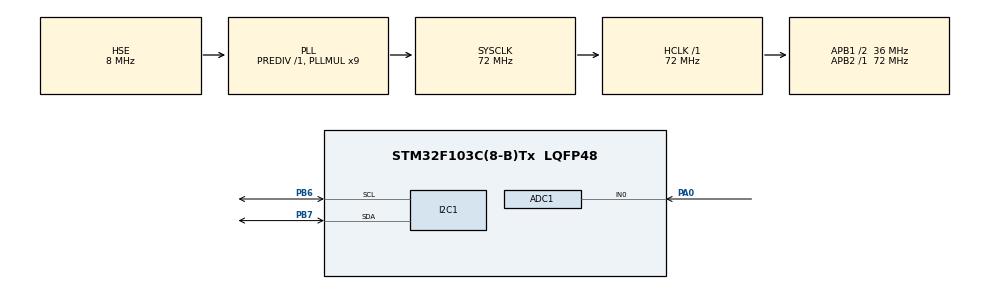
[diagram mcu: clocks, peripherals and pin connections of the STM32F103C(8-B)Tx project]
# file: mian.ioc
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ADC1.Channel-0\#ChannelRegularConversion=ADC_CHANNEL_0
ADC1.NbrOfConversionFlag=1
ADC1.Rank-0\#ChannelRegularConversion=1
ADC1.SamplingTime-0\#ChannelRegularConversion=ADC_SAMPLETIME_1CYCLE_5
ADC1.master=1
Mcu.Family=STM32F1
Mcu.Name=STM32F103C(8-B)Tx
Mcu.Package=LQFP48
NVIC.PriorityGroup=NVIC_PRIORITYGROUP_4
PA0-WKUP.Signal=ADCx_IN0
PA13.Mode=Serial_Wire
PA13.Signal=SYS_JTMS-SWDIO
PA14.Mode=Serial_Wire
PA14.Signal=SYS_JTCK-SWCLK
PB6.Mode=I2C
PB6.Signal=I2C1_SCL
PB7.Mode=I2C
PB7.Signal=I2C1_SDA
PC14-OSC32_IN.Mode=LSE-External-Oscillator
PC14-OSC32_IN.Signal=RCC_OSC32_IN
PC15-OSC32_OUT.Mode=LSE-External-Oscillator
PC15-OSC32_OUT.Signal=RCC_OSC32_OUT
PD0-OSC_IN.Mode=HSE-External-Oscillator
PD0-OSC_IN.Signal=RCC_OSC_IN
PD1-OSC_OUT.Mode=HSE-External-Oscillator
PD1-OSC_OUT.Signal=RCC_OSC_OUT
ProjectManager.HeapSize=0x200
ProjectManager.StackSize=0x400
ProjectManager.TargetToolchain=MDK-ARM V5.27
RCC.ADCPresc=RCC_ADCPCLK2_DIV6
RCC.AHBFreq_Value=72000000
RCC.APB1CLKDivider=RCC_HCLK_DIV2
RCC.APB1Freq_Value=36000000
RCC.APB1TimFreq_Value=72000000
RCC.APB2Freq_Value=72000000
RCC.APB2TimFreq_Value=72000000
RCC.HCLKFreq_Value=72000000
RCC.PLLMUL=RCC_PLL_MUL9
RCC.PLLSourceVirtual=RCC_PLLSOURCE_HSE
RCC.SYSCLKFreq_VALUE=72000000
RCC.SYSCLKSource=RCC_SYSCLKSOURCE_PLLCLK
RCC.USBFreq_Value=72000000
SH.ADCx_IN0.0=ADC1_IN0,IN0
TIM1.Prescaler=72-1
VP_TIM1_VS_ClockSourceINT.Mode=Internal
board=custom

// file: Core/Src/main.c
/* USER CODE BEGIN Header */
/**
  ******************************************************************************
  * @file           : main.c
  * @brief          : Main program body
  ******************************************************************************
  * @attention
  *
  * <h2><center>&copy; Copyright (c) 2023 STMicroelectronics.
  * All rights reserved.</center></h2>
  *
  * This software component is licensed by ST under BSD 3-Clause license,
  * the "License"; You may not use this file except in compliance with the
  * License. You may obtain a copy of the License at:
  *                        opensource.org/licenses/BSD-3-Clause
  *
  ******************************************************************************
  */
/* USER CODE END Header */
#include "main.h"
#include "adc.h"
#include "i2c.h"
#include "tim.h"
#include "gpio.h"

/* USER CODE BEGIN Includes */
#include "dht11.h"
#include "oled.h"
/* USER CODE END Includes */

void SystemClock_Config(void);

/* USER CODE BEGIN 0 */
uint16_t adc_val = 0;//define the number of getting from ADC
float adc_volt = 0;//define the voltage

int temp = 0;
int humity = 0;

/* USER CODE END 0 */

int main(void)
{

  /* MCU Configuration--------------------------------------------------------*/

  /* Reset of all peripherals, Initializes the Flash interface and the Systick. */
  HAL_Init();

  /* Configure the system clock */
  SystemClock_Config();

  /* Initialize all configured peripherals */
  MX_GPIO_Init();
  MX_ADC1_Init();
  MX_TIM1_Init();
  MX_I2C1_Init();
  /* USER CODE BEGIN 2 */
	OLED_Init();//initialize
	OLED_Clear();//clear screen
	OLED_ShowString(0, 0, "LIU", 16);// 0 1
	OLED_ShowString(0, 2, "WEI", 16);// 2

  /* USER CODE END 2 */

  /* Infinite loop */
  while (1)
  {

    /* USER CODE BEGIN 3 */
		HAL_ADC_Start(&hadc1);//turn on ADC channel
		adc_val = HAL_ADC_GetValue(&hadc1);//get the data from ADC
		adc_volt = adc_val/4096.0f * 3.3f;//trans from voltage

		DHT11_Task();
		temp = DHT11_data.temp;
		humity = DHT11_data.humidity;

		OLED_ShowNum(0, 4, temp, 2, 16);//display the temp
		OLED_ShowNum(32, 4, humity, 2, 16);//display the humity

		HAL_Delay(2000);
  }
  /* USER CODE END 3 */
}

void SystemClock_Config(void)
{
  RCC_OscInitTypeDef RCC_OscInitStruct = {0};
  RCC_ClkInitTypeDef RCC_ClkInitStruct = {0};
  RCC_PeriphCLKInitTypeDef PeriphClkInit = {0};

  /** Initializes the RCC Oscillators according to the specified parameters
  * in the RCC_OscInitTypeDef structure.
  */
  RCC_OscInitStruct.OscillatorType = RCC_OSCILLATORTYPE_HSE;
  RCC_OscInitStruct.HSEState = RCC_HSE_ON;
  RCC_OscInitStruct.HSEPredivValue = RCC_HSE_PREDIV_DIV1;
  RCC_OscInitStruct.HSIState = RCC_HSI_ON;
  RCC_OscInitStruct.PLL.PLLState = RCC_PLL_ON;
  RCC_OscInitStruct.PLL.PLLSource = RCC_PLLSOURCE_HSE;
  RCC_OscInitStruct.PLL.PLLMUL = RCC_PLL_MUL9;
  if (HAL_RCC_OscConfig(&RCC_OscInitStruct) != HAL_OK)
  {
    Error_Handler();
  }

  /** Initializes the CPU, AHB and APB buses clocks
  */
  RCC_ClkInitStruct.ClockType = RCC_CLOCKTYPE_HCLK|RCC_CLOCKTYPE_SYSCLK
                              |RCC_CLOCKTYPE_PCLK1|RCC_CLOCKTYPE_PCLK2;
  RCC_ClkInitStruct.SYSCLKSource = RCC_SYSCLKSOURCE_PLLCLK;
  RCC_ClkInitStruct.AHBCLKDivider = RCC_SYSCLK_DIV1;
  RCC_ClkInitStruct.APB1CLKDivider = RCC_HCLK_DIV2;
  RCC_ClkInitStruct.APB2CLKDivider = RCC_HCLK_DIV1;

  if (HAL_RCC_ClockConfig(&RCC_ClkInitStruct, FLASH_LATENCY_2) != HAL_OK)
  {
    Error_Handler();
  }
  PeriphClkInit.PeriphClockSelection = RCC_PERIPHCLK_ADC;
  PeriphClkInit.AdcClockSelection = RCC_ADCPCLK2_DIV6;
  if (HAL_RCCEx_PeriphCLKConfig(&PeriphClkInit) != HAL_OK)
  {
    Error_Handler();
  }
}

void Error_Handler(void)
{
  __disable_irq();
  while (1)
  {
  }
}
